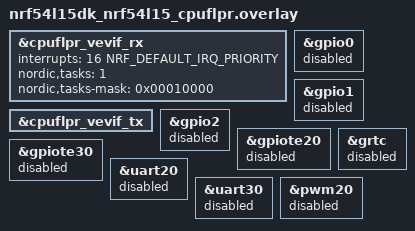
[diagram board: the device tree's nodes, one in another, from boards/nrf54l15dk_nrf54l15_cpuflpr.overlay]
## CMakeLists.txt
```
#
# Copyright (c) 2024 Nordic Semiconductor ASA
#
# SPDX-License-Identifier: LicenseRef-Nordic-5-Clause
#

cmake_minimum_required(VERSION 3.20.0)

find_package(Zephyr REQUIRED HINTS $ENV{ZEPHYR_BASE})
project(hpf_gpio)

hpf_assembly_install(app "${CMAKE_SOURCE_DIR}/src/hrt/hrt.c")

target_sources(app PRIVATE src/main.c)

target_sources_ifdef(CONFIG_HPF_GPIO_BACKEND_ICMSG app PRIVATE src/backend/backend_icmsg.c)
target_sources_ifdef(CONFIG_HPF_GPIO_BACKEND_ICBMSG app PRIVATE src/backend/backend_icmsg.c)
target_sources_ifdef(CONFIG_HPF_GPIO_BACKEND_MBOX app PRIVATE  src/backend/backend_mbox.c)
```

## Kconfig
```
choice HPF_GPIO_BACKEND
	prompt "Backend"
	default HPF_GPIO_BACKEND_ICMSG

config HPF_GPIO_BACKEND_MBOX
	bool "mbox"

config HPF_GPIO_BACKEND_ICMSG
	bool "icmsg"
	select IPC_SERVICE

config HPF_GPIO_BACKEND_ICBMSG
	bool "icbmsg"
	select IPC_SERVICE

endchoice

config HPF_DEVELOPER_MODE
	bool "HPF developer mode"
	help
	  High Performance Framework developer mode.
	  If enabled, changes in HRT files will be included in build.
	  Otherwise, if there is a change in HRT that produces a different ASM file than
	  the provided one, build error is reported.

source "Kconfig.zephyr"
```

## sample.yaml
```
sample:
  name: HPF GPIO application
  description: HPF GPIO application
common:
  integration_platforms:
    - nrf54l15dk/nrf54l15/cpuflpr
tests:
  applications.hpf.gpio.mbox:
    build_only: true
    sysbuild: true
    platform_allow: nrf54l15dk/nrf54l15/cpuflpr
    tags:
      - ci_build
      - sysbuild
      - gpio
      - ci_applications_hpf
    required_snippets:
      - hpf-gpio-mbox

  applications.hpf.gpio.icmsg:
    build_only: true
    sysbuild: true
    platform_allow: nrf54l15dk/nrf54l15/cpuflpr
    tags:
      - ci_build
      - sysbuild
      - gpio
      - ci_applications_hpf
    required_snippets:
      - hpf-gpio-icmsg

  applications.hpf.gpio.icbmsg:
    sysbuild: true
    build_only: true
    platform_allow: nrf54l15dk/nrf54l15/cpuflpr
    tags:
      - ci_build
      - sysbuild
      - gpio
      - ci_applications_hpf
    required_snippets:
      - hpf-gpio-icbmsg
```

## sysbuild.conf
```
SB_CONFIG_VPR_LAUNCHER=n
SB_CONFIG_PARTITION_MANAGER=n
```

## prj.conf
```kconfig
CONFIG_MBOX=y
```

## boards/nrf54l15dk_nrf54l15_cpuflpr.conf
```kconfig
# Single-threaded
CONFIG_MULTITHREADING=n
CONFIG_KERNEL_MEM_POOL=n
CONFIG_LOG=n

# Drivers and peripherals
CONFIG_I2C=n
CONFIG_WATCHDOG=n
CONFIG_GPIO=n
CONFIG_PINCTRL=n
CONFIG_SPI=n
CONFIG_SERIAL=n
CONFIG_FLASH=n

# Power management
CONFIG_PM=n

# Interrupts
CONFIG_DYNAMIC_INTERRUPTS=n
CONFIG_IRQ_OFFLOAD=n
CONFIG_GEN_SW_ISR_TABLE=n

# Memory protection
CONFIG_THREAD_STACK_INFO=n
CONFIG_THREAD_CUSTOM_DATA=n
CONFIG_FPU=n

# Boot
CONFIG_BOOT_BANNER=n
CONFIG_NCS_BOOT_BANNER=n

# Console
CONFIG_CONSOLE=n
CONFIG_UART_CONSOLE=n
CONFIG_STDOUT_CONSOLE=n
CONFIG_PRINTK=n
CONFIG_EARLY_CONSOLE=n

# Build
CONFIG_SIZE_OPTIMIZATIONS=y

# No timer support in the kernel
CONFIG_SYS_CLOCK_EXISTS=n

CONFIG_OUTPUT_DISASSEMBLY=y
CONFIG_COMMON_LIBC_MALLOC=n
```

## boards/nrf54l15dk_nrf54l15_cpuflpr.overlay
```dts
/*
 * Copyright (c) 2024 Nordic Semiconductor ASA
 *
 * SPDX-License-Identifier: LicenseRef-Nordic-5-Clause
 */

&cpuflpr_vevif_rx {
	status = "okay";
	interrupts = <16 NRF_DEFAULT_IRQ_PRIORITY>;
	nordic,tasks = <1>;
	nordic,tasks-mask = <0x00010000>;
};

&cpuflpr_vevif_tx {
	status = "okay";
};

&gpio0 {
	status = "disabled";
};

&gpio1 {
	status = "disabled";
};

&gpio2 {
	status = "disabled";
};

&gpiote20 {
	status = "disabled";
};

&gpiote30 {
	status = "disabled";
};

&grtc {
	status = "disabled";
};

&uart20 {
	status = "disabled";
};

&uart30 {
	status = "disabled";
};

&pwm20 {
	status = "disabled";
};
```

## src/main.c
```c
/*
 * Copyright (c) 2024 Nordic Semiconductor ASA
 *
 * SPDX-License-Identifier: LicenseRef-Nordic-5-Clause
 */

#include "./backend/backend.h"
#include "./hrt/hrt.h"

#include <zephyr/kernel.h>
#include <zephyr/drivers/gpio.h>
#include <zephyr/dt-bindings/gpio/nordic-nrf-gpio.h>
#include <drivers/gpio/hpf_gpio.h>
#include <hal/nrf_vpr_csr.h>
#include <hal/nrf_vpr_csr_vio.h>
#include <haly/nrfy_gpio.h>

#define HRT_IRQ_PRIORITY          2
#define HRT_VEVIF_IDX_GPIO_CLEAR  17
#define HRT_VEVIF_IDX_GPIO_SET    18
#define HRT_VEVIF_IDX_GPIO_TOGGLE 19

#define VEVIF_IRQN(vevif) VEVIF_IRQN_1(vevif)
#define VEVIF_IRQN_1(vevif) VPRCLIC_##vevif##_IRQn

volatile uint16_t irq_arg;

static nrf_gpio_pin_pull_t get_pull(gpio_flags_t flags)
{
	if (flags & GPIO_PULL_UP) {
		return NRF_GPIO_PIN_PULLUP;
	} else if (flags & GPIO_PULL_DOWN) {
		return NRF_GPIO_PIN_PULLDOWN;
	}

	return NRF_GPIO_PIN_NOPULL;
}

static int gpio_hpf_pin_configure(uint8_t port, uint16_t pin, uint32_t flags)
{
	if (port != 2) {
		return -EINVAL;
	}

	uint32_t abs_pin = NRF_GPIO_PIN_MAP(port, pin);
	nrf_gpio_pin_pull_t pull = get_pull(flags);
	nrf_gpio_pin_drive_t drive;

	switch (flags & (NRF_GPIO_DRIVE_MSK | GPIO_OPEN_DRAIN)) {
	case NRF_GPIO_DRIVE_S0S1:
		drive = NRF_GPIO_PIN_S0S1;
		break;
	case NRF_GPIO_DRIVE_S0H1:
		drive = NRF_GPIO_PIN_S0H1;
		break;
	case NRF_GPIO_DRIVE_H0S1:
		drive = NRF_GPIO_PIN_H0S1;
		break;
	case NRF_GPIO_DRIVE_H0H1:
		drive = NRF_GPIO_PIN_H0H1;
		break;
	case NRF_GPIO_DRIVE_S0 | GPIO_OPEN_DRAIN:
		drive = NRF_GPIO_PIN_S0D1;
		break;
	case NRF_GPIO_DRIVE_H0 | GPIO_OPEN_DRAIN:
		drive = NRF_GPIO_PIN_H0D1;
		break;
	case NRF_GPIO_DRIVE_S1 | GPIO_OPEN_SOURCE:
		drive = NRF_GPIO_PIN_D0S1;
		break;
	case NRF_GPIO_DRIVE_H1 | GPIO_OPEN_SOURCE:
		drive = NRF_GPIO_PIN_D0H1;
		break;
	default:
		return -EINVAL;
	}

	if (flags & GPIO_OUTPUT_INIT_HIGH) {
		uint16_t outs = nrf_vpr_csr_vio_out_get();

		nrf_vpr_csr_vio_out_set(outs | (BIT(pin)));
	} else if (flags & GPIO_OUTPUT_INIT_LOW) {
		uint16_t outs = nrf_vpr_csr_vio_out_get();

		nrf_vpr_csr_vio_out_set(outs & ~(BIT(pin)));
	}

	nrf_gpio_pin_dir_t dir =
		(flags & GPIO_OUTPUT) ? NRF_GPIO_PIN_DIR_OUTPUT : NRF_GPIO_PIN_DIR_INPUT;
	nrf_gpio_pin_input_t input =
		(flags & GPIO_INPUT) ? NRF_GPIO_PIN_INPUT_CONNECT : NRF_GPIO_PIN_INPUT_DISCONNECT;

	/* Reconfigure the GPIO pin with the specified pull-up/pull-down configuration and drive
	 * strength.
	 */
	nrfy_gpio_reconfigure(abs_pin, &dir, &input, &pull, &drive, NULL);

	if (dir == NRF_GPIO_PIN_DIR_OUTPUT) {
		nrf_vpr_csr_vio_dir_set(nrf_vpr_csr_vio_dir_get() | (BIT(pin)));
	}

	/* Take control of the pin */
	nrfy_gpio_pin_control_select(abs_pin, NRF_GPIO_PIN_SEL_VPR);

	return 0;
}

void process_packet(hpf_gpio_data_packet_t *packet)
{
	if (packet->port != 2) {
		return;
	}

	switch (packet->opcode) {
	case HPF_GPIO_PIN_CONFIGURE: {
		gpio_hpf_pin_configure(packet->port, packet->pin, packet->flags);
		break;
	}
	case HPF_GPIO_PIN_CLEAR: {
		irq_arg = packet->pin;
		nrf_vpr_clic_int_pending_set(NRF_VPRCLIC, VEVIF_IRQN(HRT_VEVIF_IDX_GPIO_CLEAR));
		break;
	}
	case HPF_GPIO_PIN_SET: {
		irq_arg = packet->pin;
		nrf_vpr_clic_int_pending_set(NRF_VPRCLIC, VEVIF_IRQN(HRT_VEVIF_IDX_GPIO_SET));
		break;
	}
	case HPF_GPIO_PIN_TOGGLE: {
		irq_arg = packet->pin;
		nrf_vpr_clic_int_pending_set(NRF_VPRCLIC, VEVIF_IRQN(HRT_VEVIF_IDX_GPIO_TOGGLE));
		break;
	}
	default: {
		break;
	}
	}
}

#define HRT_CONNECT(vevif, handler)                                            \
	IRQ_DIRECT_CONNECT(vevif, HRT_IRQ_PRIORITY, handler, 0);               \
	nrf_vpr_clic_int_enable_set(NRF_VPRCLIC, VEVIF_IRQN(vevif), true)


__attribute__ ((interrupt)) void hrt_handler_clear_bits(void)
{
	hrt_clear_bits();
}

__attribute__ ((interrupt)) void hrt_handler_set_bits(void)
{
	hrt_set_bits();
}

__attribute__ ((interrupt)) void hrt_handler_toggle_bits(void)
{
	hrt_toggle_bits();
}

int main(void)
{
	int ret = 0;

	ret = backend_init(process_packet);
	if (ret < 0) {
		return 0;
	}

	HRT_CONNECT(HRT_VEVIF_IDX_GPIO_CLEAR, hrt_handler_clear_bits);
	HRT_CONNECT(HRT_VEVIF_IDX_GPIO_SET, hrt_handler_set_bits);
	HRT_CONNECT(HRT_VEVIF_IDX_GPIO_TOGGLE, hrt_handler_toggle_bits);

	nrf_vpr_csr_rtperiph_enable_set(true);

	while (true) {
		k_cpu_idle();
	}

	return 0;
}
```
